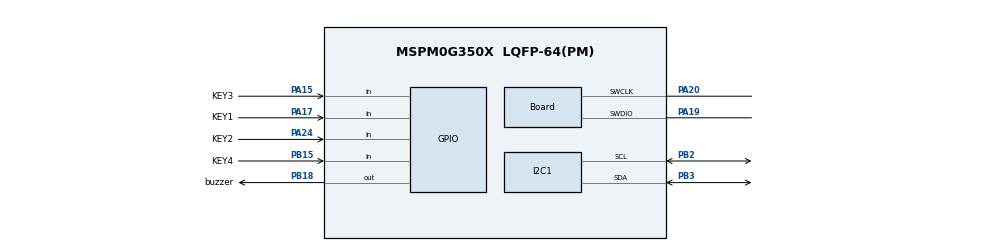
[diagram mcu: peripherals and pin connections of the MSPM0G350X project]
/**
 * @cliArgs --device "MSPM0G350X" --package "LQFP-64(PM)" --part "Default" --product "mspm0_sdk@2.00.01.00"
 * @versions {"tool":"1.20.0+3587"}
 */

/**
 * Import the modules used in this configuration.
 */
const GPIO          = scripting.addModule("/ti/driverlib/GPIO", {}, false);
const GPIO1         = GPIO.addInstance();
const GPIO2         = GPIO.addInstance();
const GPIO3         = GPIO.addInstance();
const GPIO4         = GPIO.addInstance();
const GPIO5         = GPIO.addInstance();
const I2C           = scripting.addModule("/ti/driverlib/I2C", {}, false);
const I2C1          = I2C.addInstance();
const SYSCTL        = scripting.addModule("/ti/driverlib/SYSCTL");
const TIMER         = scripting.addModule("/ti/driverlib/TIMER", {}, false);
const TIMER1        = TIMER.addInstance();
const ProjectConfig = scripting.addModule("/ti/project_config/ProjectConfig");

/**
 * Write custom configuration values to the imported modules.
 */
GPIO1.$name                          = "Right_Motor";
GPIO1.associatedPins[0].$name        = "Driver_R";
GPIO1.associatedPins[0].ioStructure  = "HS";
GPIO1.associatedPins[0].assignedPort = "PORTA";
GPIO1.associatedPins[0].assignedPin  = "13";

const Board                       = scripting.addModule("/ti/driverlib/Board", {}, false);
Board.peripheral.$assign          = "DEBUGSS";
Board.peripheral.swclkPin.$assign = "PA20";
Board.peripheral.swdioPin.$assign = "PA19";

GPIO2.$name                          = "Left_Motor";
GPIO2.associatedPins[0].$name        = "Dirver_L";
GPIO2.associatedPins[0].assignedPort = "PORTA";
GPIO2.associatedPins[0].assignedPin  = "12";
GPIO2.associatedPins[0].ioStructure  = "HS";

GPIO3.$name                          = "LED";
GPIO3.port                           = "PORTA";
GPIO3.associatedPins[0].initialValue = "SET";
GPIO3.associatedPins[0].assignedPin  = "0";
GPIO3.associatedPins[0].$name        = "LED_1";

GPIO4.$name                         = "BUZZER";
GPIO4.port                          = "PORTB";
GPIO4.associatedPins[0].$name       = "buzzer";
GPIO4.associatedPins[0].pin.$assign = "PB18";

GPIO5.$name                              = "KEY";
GPIO5.associatedPins.create(4);
GPIO5.associatedPins[0].$name            = "KEY1";
GPIO5.associatedPins[0].direction        = "INPUT";
GPIO5.associatedPins[0].internalResistor = "PULL_UP";
GPIO5.associatedPins[0].pin.$assign      = "PA17";
GPIO5.associatedPins[1].$name            = "KEY2";
GPIO5.associatedPins[1].internalResistor = "PULL_UP";
GPIO5.associatedPins[1].direction        = "INPUT";
GPIO5.associatedPins[1].pin.$assign      = "PA24";
GPIO5.associatedPins[2].$name            = "KEY3";
GPIO5.associatedPins[2].internalResistor = "PULL_UP";
GPIO5.associatedPins[2].direction        = "INPUT";
GPIO5.associatedPins[2].pin.$assign      = "PA15";
GPIO5.associatedPins[3].$name            = "KEY4";
GPIO5.associatedPins[3].internalResistor = "PULL_UP";
GPIO5.associatedPins[3].direction        = "INPUT";
GPIO5.associatedPins[3].pin.$assign      = "PB15";

I2C1.$name                     = "I2C_0";
I2C1.basicEnableController     = true;
I2C1.peripheral.sdaPin.$assign = "PB3";
I2C1.peripheral.sclPin.$assign = "PB2";
I2C1.sdaPinConfig.$name        = "ti_driverlib_gpio_GPIOPinGeneric0";
I2C1.sclPinConfig.$name        = "ti_driverlib_gpio_GPIOPinGeneric1";

SYSCTL.clockTreeEn = true;

TIMER1.$name              = "TIMER_0";
TIMER1.timerClkPrescale   = 100;
TIMER1.timerMode          = "PERIODIC_UP";
TIMER1.interrupts         = ["ZERO"];
TIMER1.timerPeriod        = "0.125ms";
TIMER1.peripheral.$assign = "TIMG0";

ProjectConfig.deviceSpin = "MSPM0G3507";

/**
 * Pinmux solution for unlocked pins/peripherals. This ensures that minor changes to the automatic solver in a future
 * version of the tool will not impact the pinmux you originally saw.  These lines can be completely deleted in order to
 * re-solve from scratch.
 */
GPIO1.associatedPins[0].pin.$suggestSolution = "PA13";
GPIO2.associatedPins[0].pin.$suggestSolution = "PA12";
GPIO3.associatedPins[0].pin.$suggestSolution = "PA0";
I2C1.peripheral.$suggestSolution             = "I2C1";
